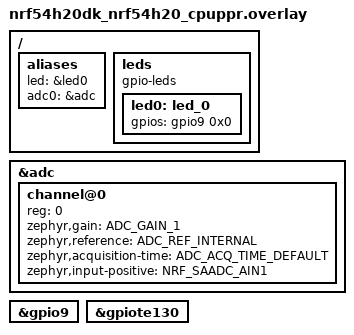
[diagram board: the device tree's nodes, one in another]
/ {
	aliases {
		led = &led0;
		adc0 = &adc;
	};

	leds {
		compatible = "gpio-leds";

		led0: led_0 {
			gpios = <&gpio9 0x0 0x0>;
		};
	};
};

&adc {
	#address-cells = <1>;
	#size-cells = <0>;
	status = "okay";

	channel@0 {
		reg = <0>;
		zephyr,gain = "ADC_GAIN_1";
		zephyr,reference = "ADC_REF_INTERNAL";
		zephyr,acquisition-time = <ADC_ACQ_TIME_DEFAULT>;
		zephyr,input-positive = <NRF_SAADC_AIN1>;
	};
};

&gpio9 {
	status = "okay";
};

&gpiote130 {
	status = "okay";
};
